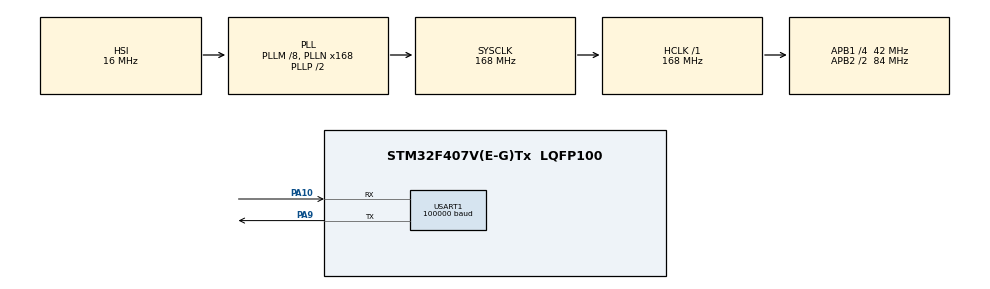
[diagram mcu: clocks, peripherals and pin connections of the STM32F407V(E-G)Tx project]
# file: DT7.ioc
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Dma.Request0=USART1_RX
Dma.USART1_RX.0.Direction=DMA_PERIPH_TO_MEMORY
Dma.USART1_RX.0.FIFOMode=DMA_FIFOMODE_DISABLE
Dma.USART1_RX.0.Instance=DMA2_Stream2
Dma.USART1_RX.0.MemDataAlignment=DMA_MDATAALIGN_BYTE
Dma.USART1_RX.0.MemInc=DMA_MINC_ENABLE
Dma.USART1_RX.0.Mode=DMA_CIRCULAR
Dma.USART1_RX.0.PeriphDataAlignment=DMA_PDATAALIGN_BYTE
Dma.USART1_RX.0.PeriphInc=DMA_PINC_DISABLE
Dma.USART1_RX.0.Priority=DMA_PRIORITY_VERY_HIGH
Mcu.Family=STM32F4
Mcu.Name=STM32F407V(E-G)Tx
Mcu.Package=LQFP100
NVIC.DMA2_Stream2_IRQn=true\:0\:0\:false\:false\:true\:false\:true\:true
NVIC.PriorityGroup=NVIC_PRIORITYGROUP_4
NVIC.USART1_IRQn=true\:0\:0\:false\:false\:true\:true\:true\:true
PA10.Mode=Asynchronous
PA10.Signal=USART1_RX
PA13.Mode=Serial_Wire
PA13.Signal=SYS_JTMS-SWDIO
PA14.Mode=Serial_Wire
PA14.Signal=SYS_JTCK-SWCLK
PA9.Mode=Asynchronous
PA9.Signal=USART1_TX
PH0-OSC_IN.Mode=HSE-External-Oscillator
PH0-OSC_IN.Signal=RCC_OSC_IN
PH1-OSC_OUT.Mode=HSE-External-Oscillator
PH1-OSC_OUT.Signal=RCC_OSC_OUT
ProjectManager.HeapSize=0x200
ProjectManager.StackSize=0x400
ProjectManager.TargetToolchain=MDK-ARM V5.32
RCC.48MHZClocksFreq_Value=84000000
RCC.AHBFreq_Value=168000000
RCC.APB1CLKDivider=RCC_HCLK_DIV4
RCC.APB1Freq_Value=42000000
RCC.APB1TimFreq_Value=84000000
RCC.APB2CLKDivider=RCC_HCLK_DIV2
RCC.APB2Freq_Value=84000000
RCC.APB2TimFreq_Value=168000000
RCC.CortexFreq_Value=168000000
RCC.HCLKFreq_Value=168000000
RCC.HSE_VALUE=8000000
RCC.HSI_VALUE=16000000
RCC.LSE_VALUE=32768
RCC.PLLM=8
RCC.PLLN=168
RCC.SYSCLKFreq_VALUE=168000000
RCC.SYSCLKSource=RCC_SYSCLKSOURCE_PLLCLK
RCC.VCOOutputFreq_Value=336000000
USART1.BaudRate=100000
USART1.Parity=PARITY_EVEN
USART1.VirtualMode=VM_ASYNC
USART1.WordLength=WORDLENGTH_9B
board=custom

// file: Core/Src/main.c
/* USER CODE BEGIN Header */
/**
  ******************************************************************************
  * @file           : main.c
  * @brief          : Main program body
  ******************************************************************************
  * @attention
  *
  * Copyright (c) 2024 STMicroelectronics.
  * All rights reserved.
  *
  * This software is licensed under terms that can be found in the LICENSE file
  * in the root directory of this software component.
  * If no LICENSE file comes with this software, it is provided AS-IS.
  *
  ******************************************************************************
  */
/* USER CODE END Header */
#include "main.h"
#include "dma.h"
#include "usart.h"
#include "gpio.h"

/* USER CODE BEGIN PTD */
#define __packed
typedef __packed struct
{
	struct  //遥控
	{
		int16_t ch[5];  //摇杆
		char s[2];  //三位开关
	}rc;

	struct  //鼠标
	{
		int16_t x;
		int16_t y;
		int16_t z;
		uint8_t press_l;
		uint8_t press_r;
	}mouse;

	struct
	{
		uint16_t v;
	}key;
}RC_ctl_t;
/* USER CODE END PTD */

/* USER CODE BEGIN PD */
#define SBUS_RX_BUF_NUM 36u
#define SBUS_FRAME_LENGTH 18u
/* ----------------------- RC Channel Definition---------------------------- */
#define RC_CH_VALUE_MIN ((uint16_t)364 )  //摇杆最小值
#define RC_CH_VALUE_OFFSET ((uint16_t)1024)  //摇杆中值
#define RC_CH_VALUE_MAX ((uint16_t)1684)  //摇杆最大值
/* ----------------------- RC Switch Definition----------------------------- */
//三位开关档位
#define RC_SW_UP ((uint16_t)1)
#define RC_SW_MID ((uint16_t)3)
#define RC_SW_DOWN ((uint16_t)2)
/* ----------------------- PC Key Definition-------------------------------- */
#define KEY_PRESSED_OFFSET_W ((uint16_t)0x01<<0)
#define KEY_PRESSED_OFFSET_S ((uint16_t)0x01<<1)
#define KEY_PRESSED_OFFSET_A ((uint16_t)0x01<<2)
#define KEY_PRESSED_OFFSET_D ((uint16_t)0x01<<3)
#define KEY_PRESSED_OFFSET_Q ((uint16_t)0x01<<4)
#define KEY_PRESSED_OFFSET_E ((uint16_t)0x01<<5)
#define KEY_PRESSED_OFFSET_SHIFT ((uint16_t)0x01<<6)
#define KEY_PRESSED_OFFSET_CTRL ((uint16_t)0x01<<7)
#define RC_FRAME_LENGTH 18u
/* USER CODE END PD */

/* USER CODE BEGIN PV */
uint8_t sbus_buf[18];  //存放接收值
RC_ctl_t rc_ctrl;      //存放解析后的值
/* USER CODE END PV */

void SystemClock_Config(void);
/* USER CODE BEGIN PFP */
void sbus_to_rc(volatile const uint8_t *sbus_buf, RC_ctl_t *rc_ctrl)
{
	if (sbus_buf == NULL || rc_ctrl == NULL)
	{
		return;
	}

	rc_ctrl->rc.ch[0] = (sbus_buf[0] | (sbus_buf[1] << 8)) & 0x07ff; //!< Channel 0
	rc_ctrl->rc.ch[1] = ((sbus_buf[1] >> 3) | (sbus_buf[2] << 5)) & 0x07ff; //!< Channel 1
	rc_ctrl->rc.ch[2] = ((sbus_buf[2] >> 6) | (sbus_buf[3] << 2) | //!< Channel 2
	(sbus_buf[4] << 10)) &0x07ff;
	rc_ctrl->rc.ch[3] = ((sbus_buf[4] >> 1) | (sbus_buf[5] << 7)) & 0x07ff; //!< Channel 3
	rc_ctrl->rc.s[0] = ((sbus_buf[5] >> 4) & 0x0003); //!< Switch left
	rc_ctrl->rc.s[1] = ((sbus_buf[5] >> 4) & 0x000C) >> 2; //!< Switch right
	rc_ctrl->mouse.x = sbus_buf[6] | (sbus_buf[7] << 8); //!< Mouse X axis
	rc_ctrl->mouse.y = sbus_buf[8] | (sbus_buf[9] << 8); //!< Mouse Y axis
	rc_ctrl->mouse.z = sbus_buf[10] | (sbus_buf[11] << 8); //!< Mouse Z axis
	rc_ctrl->mouse.press_l = sbus_buf[12]; //!< Mouse Left Is Press ?
	rc_ctrl->mouse.press_r = sbus_buf[13]; //!< Mouse Right Is Press ?
	rc_ctrl->key.v = sbus_buf[14] | (sbus_buf[15] << 8); //!< KeyBoard value
	rc_ctrl->rc.ch[4] = sbus_buf[16] | (sbus_buf[17] << 8); //NULL

	rc_ctrl->rc.ch[0] -= RC_CH_VALUE_OFFSET;
	rc_ctrl->rc.ch[1] -= RC_CH_VALUE_OFFSET;
	rc_ctrl->rc.ch[2] -= RC_CH_VALUE_OFFSET;
	rc_ctrl->rc.ch[3] -= RC_CH_VALUE_OFFSET;
	rc_ctrl->rc.ch[4] -= RC_CH_VALUE_OFFSET;
}
/* USER CODE END PFP */

int main(void)
{

  /* MCU Configuration--------------------------------------------------------*/

  /* Reset of all peripherals, Initializes the Flash interface and the Systick. */
  HAL_Init();

  /* Configure the system clock */
  SystemClock_Config();

  /* Initialize all configured peripherals */
  MX_GPIO_Init();
  MX_DMA_Init();
  MX_USART1_UART_Init();
  /* USER CODE BEGIN 2 */
	HAL_UARTEx_ReceiveToIdle_DMA(&huart1, sbus_buf, sizeof(sbus_buf));
  /* USER CODE END 2 */

  /* Infinite loop */
  while (1)
  {

  }
}

void SystemClock_Config(void)
{
  RCC_OscInitTypeDef RCC_OscInitStruct = {0};
  RCC_ClkInitTypeDef RCC_ClkInitStruct = {0};

  /** Configure the main internal regulator output voltage
  */
  __HAL_RCC_PWR_CLK_ENABLE();
  __HAL_PWR_VOLTAGESCALING_CONFIG(PWR_REGULATOR_VOLTAGE_SCALE1);

  /** Initializes the RCC Oscillators according to the specified parameters
  * in the RCC_OscInitTypeDef structure.
  */
  RCC_OscInitStruct.OscillatorType = RCC_OSCILLATORTYPE_HSI;
  RCC_OscInitStruct.HSIState = RCC_HSI_ON;
  RCC_OscInitStruct.HSICalibrationValue = RCC_HSICALIBRATION_DEFAULT;
  RCC_OscInitStruct.PLL.PLLState = RCC_PLL_ON;
  RCC_OscInitStruct.PLL.PLLSource = RCC_PLLSOURCE_HSI;
  RCC_OscInitStruct.PLL.PLLM = 8;
  RCC_OscInitStruct.PLL.PLLN = 168;
  RCC_OscInitStruct.PLL.PLLP = RCC_PLLP_DIV2;
  RCC_OscInitStruct.PLL.PLLQ = 4;
  if (HAL_RCC_OscConfig(&RCC_OscInitStruct) != HAL_OK)
  {
    Error_Handler();
  }

  /** Initializes the CPU, AHB and APB buses clocks
  */
  RCC_ClkInitStruct.ClockType = RCC_CLOCKTYPE_HCLK|RCC_CLOCKTYPE_SYSCLK
                              |RCC_CLOCKTYPE_PCLK1|RCC_CLOCKTYPE_PCLK2;
  RCC_ClkInitStruct.SYSCLKSource = RCC_SYSCLKSOURCE_PLLCLK;
  RCC_ClkInitStruct.AHBCLKDivider = RCC_SYSCLK_DIV1;
  RCC_ClkInitStruct.APB1CLKDivider = RCC_HCLK_DIV4;
  RCC_ClkInitStruct.APB2CLKDivider = RCC_HCLK_DIV2;

  if (HAL_RCC_ClockConfig(&RCC_ClkInitStruct, FLASH_LATENCY_5) != HAL_OK)
  {
    Error_Handler();
  }
}

/* USER CODE BEGIN 4 */
void HAL_UARTEx_RxEventCallback(UART_HandleTypeDef *huart, uint16_t Size)
{
	if (huart == &huart1)
	{
		sbus_to_rc(sbus_buf, &rc_ctrl);
	}
}
/* USER CODE END 4 */

void Error_Handler(void)
{
  __disable_irq();
  while (1)
  {
  }
}
